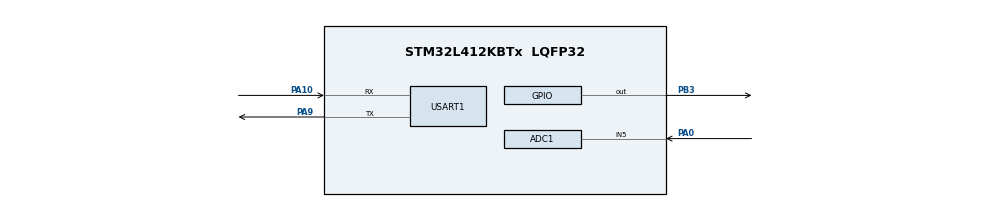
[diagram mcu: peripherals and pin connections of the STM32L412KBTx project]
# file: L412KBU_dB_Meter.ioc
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Mcu.Family=STM32L4
RCC.MSI_VALUE=4000000
FREERTOS.Tasks01=defaultTask,24,128,StartDefaultTask,Default,NULL,Dynamic,NULL,NULL
ADC1.Rank-0\#ChannelRegularConversion=1
PA10.Mode=Asynchronous
ADC1.OffsetNumber-0\#ChannelRegularConversion=ADC_OFFSET_NONE
ProjectManager.StackSize=0x400
VP_FREERTOS_VS_CMSIS_V2.Mode=CMSIS_V2
USART1.VirtualMode-Asynchronous=VM_ASYNC
PA9.Mode=Asynchronous
ProjectManager.TargetToolchain=STM32CubeIDE
PB3\ (JTDO/TRACESWO).Signal=GPIO_Output
PA9.Signal=USART1_TX
RCC.USBFreq_Value=4000000
RCC.LSE_VALUE=32768
ADC1.Channel-0\#ChannelRegularConversion=ADC_CHANNEL_5
RCC.HSE_VALUE=8000000
board=custom
RCC.VCOOutputFreq_Value=32000000
PA0-CK_IN.Signal=ADCx_IN5
VP_SYS_VS_tim1.Mode=TIM1
RCC.ADCFreq_Value=4000000
Mcu.Name=STM32L412KBTx
ADC1.SamplingTime-0\#ChannelRegularConversion=ADC_SAMPLETIME_2CYCLES_5
Mcu.Package=LQFP32
ADC1.master=1
NVIC.TimeBase=TIM1_UP_TIM16_IRQn
NVIC.TimeBaseIP=TIM1
PA10.Signal=USART1_RX
ProjectManager.HeapSize=0x200
RCC.HSI_VALUE=16000000
SH.ADCx_IN5.0=ADC1_IN5,IN5-Single-Ended
NVIC.TIM1_UP_TIM16_IRQn=true\:0\:0\:false\:false\:true\:false\:false\:true
NVIC.PriorityGroup=NVIC_PRIORITYGROUP_4
ADC1.NbrOfConversionFlag=1
RCC.HSI48_VALUE=48000000

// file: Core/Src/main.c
/* USER CODE BEGIN Header */
/**
  ******************************************************************************
  * @file           : main.c
  * @brief          : Main program body
  ******************************************************************************
  * @attention
  *
  * <h2><center>&copy; Copyright (c) 2023 STMicroelectronics.
  * All rights reserved.</center></h2>
  *
  * This software component is licensed by ST under BSD 3-Clause license,
  * the "License"; You may not use this file except in compliance with the
  * License. You may obtain a copy of the License at:
  *                        opensource.org/licenses/BSD-3-Clause
  *
  ******************************************************************************
  */
/* USER CODE END Header */
#include "main.h"
#include "cmsis_os.h"

/* USER CODE BEGIN Includes */
#include "timer_task_user.h"
#include "system_task_user.h"
#include "auxiliary_task_user.h"
#include "error.h"
/* USER CODE END Includes */

ADC_HandleTypeDef hadc1;

UART_HandleTypeDef huart1;

/* Definitions for defaultTask */
osThreadId_t defaultTaskHandle;
const osThreadAttr_t defaultTask_attributes = {
  .name = "defaultTask",
  .stack_size = 128 * 4,
  .priority = (osPriority_t) osPriorityNormal,
};

void SystemClock_Config(void);
static void MX_GPIO_Init(void);
static void MX_USART1_UART_Init(void);
static void MX_ADC1_Init(void);
void StartDefaultTask(void *argument);

int main(void)
{

  /* MCU Configuration--------------------------------------------------------*/

  /* Reset of all peripherals, Initializes the Flash interface and the Systick. */
  HAL_Init();

  /* Configure the system clock */
  SystemClock_Config();

  /* Initialize all configured peripherals */
  MX_GPIO_Init();
  MX_USART1_UART_Init();
  MX_ADC1_Init();
  /* USER CODE BEGIN 2 */
  /* Test GPIO */
  HAL_GPIO_WritePin(GPIOB, GPIO_PIN_7, GPIO_PIN_SET);
  HAL_Delay(500);
  /* USER CODE END 2 */

  /* Init scheduler */
  osKernelInitialize();

  /* Create the thread(s) */
  /* creation of defaultTask */
  defaultTaskHandle = osThreadNew(StartDefaultTask, NULL, &defaultTask_attributes);

  /* USER CODE BEGIN RTOS_THREADS */
  /* add threads, ... */
  create_timer_task();
  create_system_task();
  create_auxiliary_task();
  start_timer_task();
  /* USER CODE END RTOS_THREADS */

  /* Start scheduler */
  osKernelStart();

  /* We should never get here as control is now taken by the scheduler */
  /* Infinite loop */
  while (1)
  {

  }
}

void SystemClock_Config(void)
{
  RCC_OscInitTypeDef RCC_OscInitStruct = {0};
  RCC_ClkInitTypeDef RCC_ClkInitStruct = {0};
  RCC_PeriphCLKInitTypeDef PeriphClkInit = {0};

  /** Configure the main internal regulator output voltage
  */
  if (HAL_PWREx_ControlVoltageScaling(PWR_REGULATOR_VOLTAGE_SCALE1) != HAL_OK)
  {
    Error_Handler();
  }
  /** Initializes the RCC Oscillators according to the specified parameters
  * in the RCC_OscInitTypeDef structure.
  */
  RCC_OscInitStruct.OscillatorType = RCC_OSCILLATORTYPE_MSI;
  RCC_OscInitStruct.MSIState = RCC_MSI_ON;
  RCC_OscInitStruct.MSICalibrationValue = 0;
  RCC_OscInitStruct.MSIClockRange = RCC_MSIRANGE_6;
  RCC_OscInitStruct.PLL.PLLState = RCC_PLL_NONE;
  if (HAL_RCC_OscConfig(&RCC_OscInitStruct) != HAL_OK)
  {
    Error_Handler();
  }
  /** Initializes the CPU, AHB and APB buses clocks
  */
  RCC_ClkInitStruct.ClockType = RCC_CLOCKTYPE_HCLK|RCC_CLOCKTYPE_SYSCLK
                              |RCC_CLOCKTYPE_PCLK1|RCC_CLOCKTYPE_PCLK2;
  RCC_ClkInitStruct.SYSCLKSource = RCC_SYSCLKSOURCE_MSI;
  RCC_ClkInitStruct.AHBCLKDivider = RCC_SYSCLK_DIV1;
  RCC_ClkInitStruct.APB1CLKDivider = RCC_HCLK_DIV1;
  RCC_ClkInitStruct.APB2CLKDivider = RCC_HCLK_DIV1;

  if (HAL_RCC_ClockConfig(&RCC_ClkInitStruct, FLASH_LATENCY_0) != HAL_OK)
  {
    Error_Handler();
  }
  PeriphClkInit.PeriphClockSelection = RCC_PERIPHCLK_USART1|RCC_PERIPHCLK_ADC;
  PeriphClkInit.Usart1ClockSelection = RCC_USART1CLKSOURCE_PCLK2;
  if (HAL_RCCEx_PeriphCLKConfig(&PeriphClkInit) != HAL_OK)
  {
    Error_Handler();
  }
}

static void MX_ADC1_Init(void)
{

  ADC_MultiModeTypeDef multimode = {0};
  ADC_ChannelConfTypeDef sConfig = {0};

  /** Common config
  */
  hadc1.Instance = ADC1;
  hadc1.Init.ClockPrescaler = ADC_CLOCK_ASYNC_DIV1;
  hadc1.Init.Resolution = ADC_RESOLUTION_12B;
  hadc1.Init.DataAlign = ADC_DATAALIGN_RIGHT;
  hadc1.Init.ScanConvMode = ADC_SCAN_DISABLE;
  hadc1.Init.EOCSelection = ADC_EOC_SINGLE_CONV;
  hadc1.Init.LowPowerAutoWait = DISABLE;
  hadc1.Init.ContinuousConvMode = DISABLE;
  hadc1.Init.NbrOfConversion = 1;
  hadc1.Init.DiscontinuousConvMode = DISABLE;
  hadc1.Init.ExternalTrigConv = ADC_SOFTWARE_START;
  hadc1.Init.ExternalTrigConvEdge = ADC_EXTERNALTRIGCONVEDGE_NONE;
  hadc1.Init.DMAContinuousRequests = DISABLE;
  hadc1.Init.Overrun = ADC_OVR_DATA_PRESERVED;
  hadc1.Init.OversamplingMode = DISABLE;
  if (HAL_ADC_Init(&hadc1) != HAL_OK)
  {
    Error_Handler();
  }
  /** Configure the ADC multi-mode
  */
  multimode.Mode = ADC_MODE_INDEPENDENT;
  if (HAL_ADCEx_MultiModeConfigChannel(&hadc1, &multimode) != HAL_OK)
  {
    Error_Handler();
  }
  /** Configure Regular Channel
  */
  sConfig.Channel = ADC_CHANNEL_5;
  sConfig.Rank = ADC_REGULAR_RANK_1;
  sConfig.SamplingTime = ADC_SAMPLETIME_2CYCLES_5;
  sConfig.SingleDiff = ADC_SINGLE_ENDED;
  sConfig.OffsetNumber = ADC_OFFSET_NONE;
  sConfig.Offset = 0;
  if (HAL_ADC_ConfigChannel(&hadc1, &sConfig) != HAL_OK)
  {
    Error_Handler();
  }

}

static void MX_USART1_UART_Init(void)
{

  huart1.Instance = USART1;
  huart1.Init.BaudRate = 115200;
  huart1.Init.WordLength = UART_WORDLENGTH_8B;
  huart1.Init.StopBits = UART_STOPBITS_1;
  huart1.Init.Parity = UART_PARITY_NONE;
  huart1.Init.Mode = UART_MODE_TX_RX;
  huart1.Init.HwFlowCtl = UART_HWCONTROL_NONE;
  huart1.Init.OverSampling = UART_OVERSAMPLING_16;
  huart1.Init.OneBitSampling = UART_ONE_BIT_SAMPLE_DISABLE;
  huart1.AdvancedInit.AdvFeatureInit = UART_ADVFEATURE_NO_INIT;
  if (HAL_UART_Init(&huart1) != HAL_OK)
  {
    Error_Handler();
  }

}

static void MX_GPIO_Init(void)
{
  GPIO_InitTypeDef GPIO_InitStruct = {0};

  /* GPIO Ports Clock Enable */
  __HAL_RCC_GPIOA_CLK_ENABLE();
  __HAL_RCC_GPIOB_CLK_ENABLE();

  /*Configure GPIO pin Output Level */
  HAL_GPIO_WritePin(GPIOB, GPIO_PIN_3, GPIO_PIN_RESET);

  /*Configure GPIO pin : PB3 */
  GPIO_InitStruct.Pin = GPIO_PIN_3;
  GPIO_InitStruct.Mode = GPIO_MODE_OUTPUT_PP;
  GPIO_InitStruct.Pull = GPIO_NOPULL;
  GPIO_InitStruct.Speed = GPIO_SPEED_FREQ_LOW;
  HAL_GPIO_Init(GPIOB, &GPIO_InitStruct);

}

void StartDefaultTask(void *argument)
{
  for(;;)
  {
    osDelay(1);
  }
}

 /**
  * @brief  Period elapsed callback in non blocking mode
  * @note   This function is called  when TIM1 interrupt took place, inside
  * HAL_TIM_IRQHandler(). It makes a direct call to HAL_IncTick() to increment
  * a global variable "uwTick" used as application time base.
  * @param  htim : TIM handle
  * @retval None
  */
void HAL_TIM_PeriodElapsedCallback(TIM_HandleTypeDef *htim)
{
  if (htim->Instance == TIM1) {
    HAL_IncTick();
  }
}

void Error_Handler(void)
{
  __disable_irq();
  while (1)
  {
  }
}

/************************ (C) COPYRIGHT STMicroelectronics *****END OF FILE****/
